VERSION ""

NS_ :

BS_:

BU_: UserApplication MCM
VAL_TABLE_ SystemState 254 "Fail Hard" 253 "Human Override" 242 "Fail Operational 2" 241 "Fail Operational 1" 1 "MCM Control" 0 "Human Control" ;
VAL_TABLE_ InterfaceState 1 "MCM Control" 0 "Human Control" ;

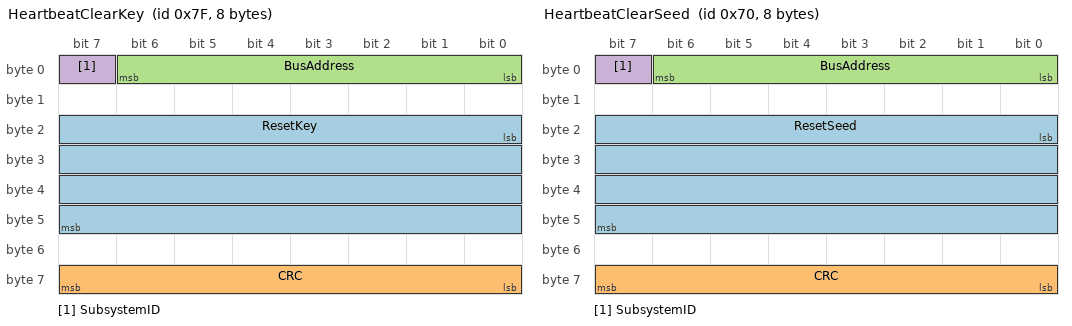
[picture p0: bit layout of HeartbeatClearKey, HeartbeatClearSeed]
BO_ 127 HeartbeatClearKey: 8 Vector__XXX
 SG_ ResetKey : 16|32@1+ (1,0) [0|0] "" Vector__XXX
 SG_ CRC : 56|8@1+ (1,0) [0|0] "" Vector__XXX
 SG_ BusAddress : 0|7@1+ (1,0) [0|0] "" Vector__XXX
 SG_ SubsystemID : 7|1@1+ (1,0) [0|0] "" Vector__XXX

BO_ 112 HeartbeatClearSeed: 8 Vector__XXX
 SG_ ResetSeed : 16|32@1+ (1,0) [0|0] "" Vector__XXX
 SG_ CRC : 56|8@1+ (1,0) [0|0] "" Vector__XXX
 SG_ BusAddress : 0|7@1+ (1,0) [0|0] "" Vector__XXX
 SG_ SubsystemID : 7|1@1+ (1,0) [0|0] "" Vector__XXX

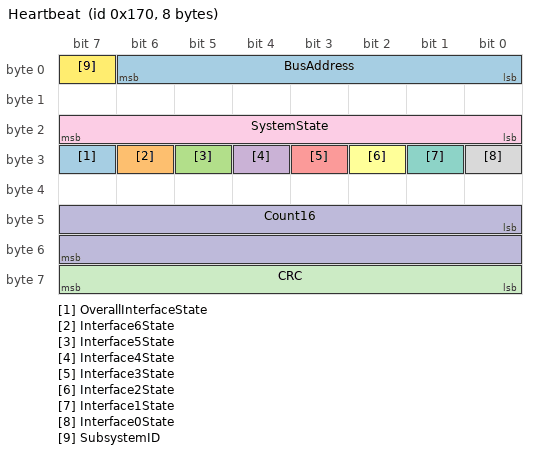
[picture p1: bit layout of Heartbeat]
BO_ 368 Heartbeat: 8 MCM
 SG_ OverallInterfaceState : 31|1@1+ (1,0) [0|0] "" Vector__XXX
 SG_ Interface6State : 30|1@1+ (1,0) [0|0] "" Vector__XXX
 SG_ Interface5State : 29|1@1+ (1,0) [0|0] "" Vector__XXX
 SG_ Interface4State : 28|1@1+ (1,0) [0|0] "" Vector__XXX
 SG_ Interface3State : 27|1@1+ (1,0) [0|0] "" Vector__XXX
 SG_ Interface2State : 26|1@1+ (1,0) [0|0] "" Vector__XXX
 SG_ Interface1State : 25|1@1+ (1,0) [0|0] "" Vector__XXX
 SG_ Interface0State : 24|1@1+ (1,0) [0|0] "" Vector__XXX
 SG_ SystemState : 16|8@1+ (1,0) [0|0] "" Vector__XXX
 SG_ Count16 : 40|16@1+ (1,0) [0|0] "" Vector__XXX
 SG_ CRC : 56|8@1+ (1,0) [0|0] "" Vector__XXX
 SG_ SubsystemID : 7|1@1+ (1,0) [0|0] "" Vector__XXX
 SG_ BusAddress : 0|7@1+ (1,0) [0|0] "" Vector__XXX

BA_DEF_ SG_  "SigType" ENUM  "Default","Range","RangeSigned","ASCII","Discrete","Control","ReferencePGN","DTC","StringDelimiter","StringLength","StringLengthControl","MessageCounter","MessageChecksum";
BA_DEF_ SG_  "GenSigEVName" STRING ;
BA_DEF_ SG_  "GenSigILSupport" ENUM  "No","Yes";
BA_DEF_ SG_  "GenSigSendType" ENUM  "Cyclic","OnWrite","OnWriteWithRepetition","OnChange","OnChangeWithRepetition","IfActive","IfActiveWithRepetition","NoSigSendType";
BA_DEF_ BO_  "GenMsgILSupport" ENUM  "No","Yes";
BA_DEF_ BU_  "NmStationAddress" INT 0 255;
BA_DEF_ BO_  "GenMsgSendType" ENUM  "cyclic","NotUsed","IfActive","NotUsed","NotUsed","NotUsed","NotUsed","NotUsed","noMsgSendType";
BA_DEF_ BO_  "GenMsgRequestable" INT 0 1;
BA_DEF_  "DBName" STRING ;
BA_DEF_  "BusType" STRING ;
BA_DEF_  "ProtocolType" STRING ;
BA_DEF_ BO_  "VFrameFormat" ENUM  "StandardCAN","ExtendedCAN","reserved","J1939PG";
BA_DEF_DEF_  "SigType" "Default";
BA_DEF_DEF_  "GenSigEVName" "Env@Nodename_@Signame";
BA_DEF_DEF_  "GenSigILSupport" "Yes";
BA_DEF_DEF_  "GenSigSendType" "NoSigSendType";
BA_DEF_DEF_  "GenMsgILSupport" "Yes";
BA_DEF_DEF_  "NmStationAddress" 254;
BA_DEF_DEF_  "GenMsgSendType" "noMsgSendType";
BA_DEF_DEF_  "GenMsgRequestable" 1;
BA_DEF_DEF_  "DBName" "";
BA_DEF_DEF_  "BusType" "CAN";
BA_DEF_DEF_  "ProtocolType" "J1939";
BA_DEF_DEF_  "VFrameFormat" "J1939PG";
BA_ "DBName" "Sygnal";
BA_ "NmStationAddress" BU_ UserApplication 241;
BA_ "NmStationAddress" BU_ MCM 0;
BA_ "VFrameFormat" BO_ 127 0;
BA_ "VFrameFormat" BO_ 112 0;
BA_ "VFrameFormat" BO_ 368 0;
VAL_ 368 OverallInterfaceState 1 "MCM Control" 0 "Human Control" ;
VAL_ 368 Interface6State 1 "MCM Control" 0 "Human Control" ;
VAL_ 368 Interface5State 1 "MCM Control" 0 "Human Control" ;
VAL_ 368 Interface4State 1 "MCM Control" 0 "Human Control" ;
VAL_ 368 Interface3State 1 "MCM Control" 0 "Human Control" ;
VAL_ 368 Interface2State 1 "MCM Control" 0 "Human Control" ;
VAL_ 368 Interface1State 1 "MCM Control" 0 "Human Control" ;
VAL_ 368 Interface0State 1 "MCM Control" 0 "Human Control" ;
VAL_ 368 SystemState 254 "Fail Hard" 253 "Human Override" 242 "Fail Operational 2" 241 "Fail Operational 1" 1 "MCM Control" 0 "Human Control" ;
